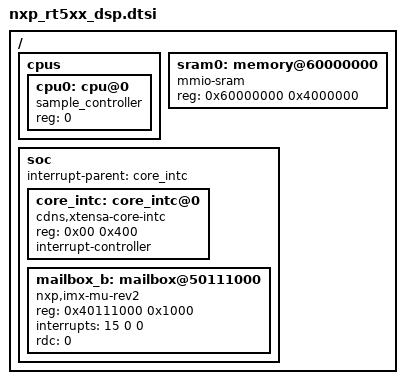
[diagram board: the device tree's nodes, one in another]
/*
 * Copyright (c) 2023 NXP
 *
 * SPDX-License-Identifier: Apache-2.0
 */

#include <xtensa/xtensa.dtsi>
#include <mem.h>

/ {
	cpus {
		#address-cells = <1>;
		#size-cells = <0>;

		cpu0: cpu@0 {
			device_type = "cpu";
			compatible = "sample_controller";
			reg = <0>;
		};
	};

	sram0: memory@60000000 {
		device_type = "memory";
		compatible = "mmio-sram";
		reg = <0x60000000 0x4000000>;
	};


	soc {
		interrupt-parent = <&core_intc>;

		core_intc: core_intc@0 {
			compatible = "cdns,xtensa-core-intc";
			reg = <0x00 0x400>;
			interrupt-controller;
			#interrupt-cells = <3>;
		};
		mailbox_b: mailbox@50111000 {
			compatible = "nxp,imx-mu-rev2";
			reg = <0x40111000 0x1000>;
			//the interrupt is not comply with real hardware(23)
			interrupts = <15 0 0>;
			rdc = <0>;
		};
	};
};
